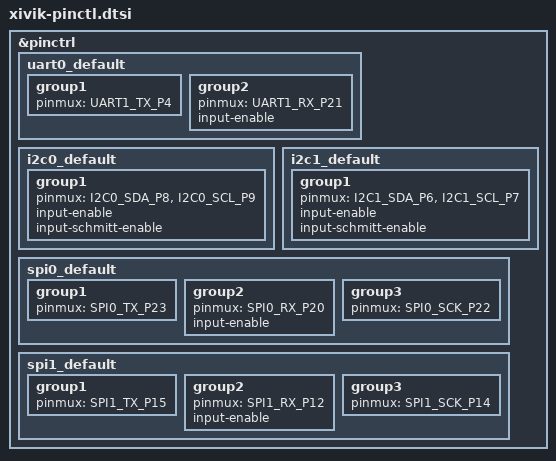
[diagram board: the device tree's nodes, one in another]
/*
 * Copyright (c) 2021, Yonatan Schachter
 * SPDX-License-Identifier: Apache-2.0
 */

#include <dt-bindings/pinctrl/rpi-pico-rp2040-pinctrl.h>

&pinctrl {
	
	uart0_default: uart0_default {
		group1 {
			pinmux = <UART1_TX_P4>;
		};
		group2 {
			pinmux = <UART1_RX_P21>;
			input-enable;
		};
	};

	// vik i2c pinout
	i2c0_default: i2c0_default {
		group1 {
			pinmux = <I2C0_SDA_P8>, <I2C0_SCL_P9>;
			input-enable;
			input-schmitt-enable;
		};
	};

	i2c1_default: i2c1_default {
		group1 {
			pinmux = <I2C1_SDA_P6>, <I2C1_SCL_P7>;
			input-enable;
			input-schmitt-enable;
		};
	};

	// through hole spi pinout
	spi0_default: spi0_default {
		group1 {
			pinmux = <SPI0_TX_P23>;
		};
		group2 {
			pinmux = <SPI0_RX_P20>;
			input-enable;
		};
		group3 {
			pinmux = <SPI0_SCK_P22>;
		};
	};

	// vik spi pinout
	spi1_default: spi1_default {
		group1 {
			pinmux = <SPI1_TX_P15>;
		};
		group2 {
			pinmux = <SPI1_RX_P12>;
			input-enable;
		};
		group3 {
			pinmux = <SPI1_SCK_P14>;
		};
	};
};
